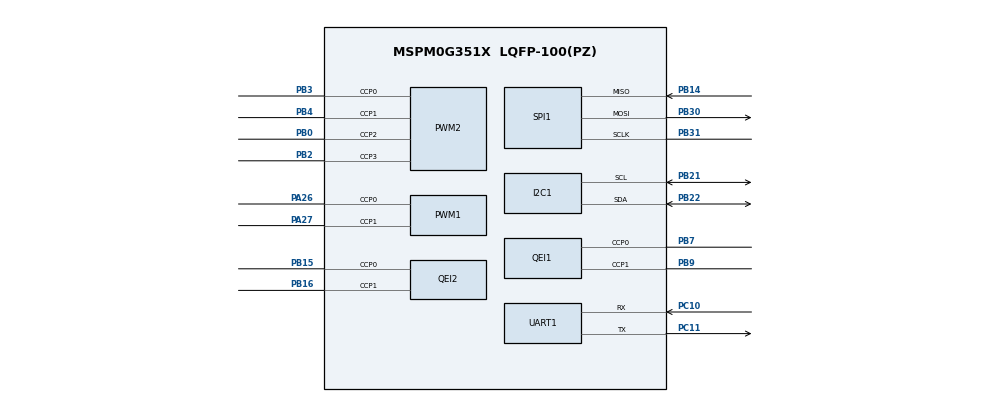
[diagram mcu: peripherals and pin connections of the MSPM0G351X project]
/**
 * @cliArgs --device "MSPM0G351X" --part "Default" --package "LQFP-100(PZ)" --product "mspm0_sdk@2.05.01.00"
 * @versions {"tool":"1.24.1+4189"}
 */

/**
 * Import the modules used in this configuration.
 */
const ADC12         = scripting.addModule("/ti/driverlib/ADC12", {}, false);
const ADC121        = ADC12.addInstance();
const Board         = scripting.addModule("/ti/driverlib/Board");
const GPIO          = scripting.addModule("/ti/driverlib/GPIO", {}, false);
const GPIO1         = GPIO.addInstance();
const GPIO2         = GPIO.addInstance();
const GPIO3         = GPIO.addInstance();
const I2C           = scripting.addModule("/ti/driverlib/I2C", {}, false);
const I2C1          = I2C.addInstance();
const PWM           = scripting.addModule("/ti/driverlib/PWM", {}, false);
const PWM1          = PWM.addInstance();
const PWM2          = PWM.addInstance();
const QEI           = scripting.addModule("/ti/driverlib/QEI", {}, false);
const QEI1          = QEI.addInstance();
const QEI2          = QEI.addInstance();
const SPI           = scripting.addModule("/ti/driverlib/SPI", {}, false);
const SPI1          = SPI.addInstance();
const SYSCTL        = scripting.addModule("/ti/driverlib/SYSCTL");
const SYSTICK       = scripting.addModule("/ti/driverlib/SYSTICK");
const UART          = scripting.addModule("/ti/driverlib/UART", {}, false);
const UART1         = UART.addInstance();
const ProjectConfig = scripting.addModule("/ti/project_config/ProjectConfig");

/**
 * Write custom configuration values to the imported modules.
 */
const divider9       = system.clockTree["UDIV"];
divider9.divideValue = 2;

const gate7  = system.clockTree["MFCLKGATE"];
gate7.enable = true;

const multiplier2         = system.clockTree["PLL_QDIV"];
multiplier2.multiplyValue = 4;

const mux4       = system.clockTree["EXHFMUX"];
mux4.inputSelect = "EXHFMUX_XTAL";

const mux5       = system.clockTree["EXLFMUX"];
mux5.inputSelect = "EXLFMUX_XTAL";

const mux8       = system.clockTree["HSCLKMUX"];
mux8.inputSelect = "HSCLKMUX_SYSPLL0";

const mux12       = system.clockTree["SYSPLLMUX"];
mux12.inputSelect = "zSYSPLLMUX_HFCLK";

const pinFunction4              = system.clockTree["HFXT"];
pinFunction4.enable             = true;
pinFunction4.inputFreq          = 40;
pinFunction4.HFXTStartup        = 16;
pinFunction4.peripheral.$assign = "SYSCTL";

const pinFunction6     = system.clockTree["LFXT"];
pinFunction6.inputFreq = 32.768;
pinFunction6.enable    = true;

ADC121.adcMem4chansel        = "DL_ADC12_INPUT_CHAN_4";
ADC121.$name                 = "CCD";
ADC121.adcMem4_name          = "CCD3_AO";
ADC121.adcMem2_name          = "CCD1_AO";
ADC121.adcMem2chansel        = "DL_ADC12_INPUT_CHAN_5";
ADC121.adcMem3_name          = "CCD2_AO";
ADC121.adcMem3chansel        = "DL_ADC12_INPUT_CHAN_6";
ADC121.adcMem6_name          = "CCD4_AO";
ADC121.adcMem6chansel        = "DL_ADC12_INPUT_CHAN_2";
ADC121.adcMem5chansel        = "DL_ADC12_INPUT_CHAN_6";
ADC121.adcMem5_name          = "CCD2_AO";
ADC121.adcMem0chansel        = "DL_ADC12_INPUT_CHAN_5";
ADC121.adcMem0_name          = "CCD1_AO";
ADC121.samplingOperationMode = "sequence";
ADC121.adcMem1_name          = "CCD2_AO";
ADC121.endAdd                = 1;
ADC121.adcMem1chansel        = "DL_ADC12_INPUT_CHAN_4";
ADC121.sampClkDiv            = "DL_ADC12_CLOCK_DIVIDE_8";
ADC121.powerDownMode         = "DL_ADC12_POWER_DOWN_MODE_MANUAL";
ADC121.sampleTime0           = "125 us";
ADC121.repeatMode            = true;
ADC121.enabledInterrupts     = ["DL_ADC12_INTERRUPT_MEM0_RESULT_LOADED","DL_ADC12_INTERRUPT_MEM1_RESULT_LOADED"];
ADC121.adcPin5Config.$name   = "ti_driverlib_gpio_GPIOPinGeneric17";
ADC121.peripheral.$assign    = "ADC1";
ADC121.adcPin4Config.$name   = "ti_driverlib_gpio_GPIOPinGeneric18";

Board.configureVDDA = true;

GPIO1.port                          = "PORTB";
GPIO1.$name                         = "PORTB";
GPIO1.associatedPins.create(5);
GPIO1.associatedPins[0].$name       = "LED";
GPIO1.associatedPins[0].ioStructure = "SD";
GPIO1.associatedPins[0].assignedPin = "5";
GPIO1.associatedPins[1].$name       = "CCD_CLK1";
GPIO1.associatedPins[1].assignedPin = "20";
GPIO1.associatedPins[2].$name       = "SLEEP";
GPIO1.associatedPins[2].assignedPin = "1";
GPIO1.associatedPins[3].$name       = "LCD_CS";
GPIO1.associatedPins[3].assignedPin = "28";
GPIO1.associatedPins[4].$name       = "LCD_DC";
GPIO1.associatedPins[4].assignedPin = "29";

GPIO2.port                          = "PORTA";
GPIO2.$name                         = "PORTA";
GPIO2.associatedPins.create(9);
GPIO2.associatedPins[0].direction   = "INPUT";
GPIO2.associatedPins[0].assignedPin = "18";
GPIO2.associatedPins[0].$name       = "S0";
GPIO2.associatedPins[1].direction   = "INPUT";
GPIO2.associatedPins[1].assignedPin = "14";
GPIO2.associatedPins[1].$name       = "PHA0";
GPIO2.associatedPins[1].interruptEn = true;
GPIO2.associatedPins[1].polarity    = "RISE_FALL";
GPIO2.associatedPins[2].$name       = "PHB0";
GPIO2.associatedPins[2].direction   = "INPUT";
GPIO2.associatedPins[2].assignedPin = "15";
GPIO2.associatedPins[3].$name       = "PUSH";
GPIO2.associatedPins[3].direction   = "INPUT";
GPIO2.associatedPins[3].assignedPin = "12";
GPIO2.associatedPins[4].$name       = "BUZZ";
GPIO2.associatedPins[4].assignedPin = "13";
GPIO2.associatedPins[5].$name       = "S2";
GPIO2.associatedPins[5].direction   = "INPUT";
GPIO2.associatedPins[5].assignedPin = "16";
GPIO2.associatedPins[6].$name       = "FAULT";
GPIO2.associatedPins[6].assignedPin = "7";
GPIO2.associatedPins[6].direction   = "INPUT";
GPIO2.associatedPins[7].$name       = "LCD_RST";
GPIO2.associatedPins[7].assignedPin = "8";
GPIO2.associatedPins[8].$name       = "LCD_BL";
GPIO2.associatedPins[8].assignedPin = "9";

GPIO3.port                          = "PORTC";
GPIO3.$name                         = "PORTC";
GPIO3.associatedPins.create(4);
GPIO3.associatedPins[0].$name       = "CCD_SI1";
GPIO3.associatedPins[0].assignedPin = "9";
GPIO3.associatedPins[1].$name       = "CCD_SI2";
GPIO3.associatedPins[1].assignedPin = "4";
GPIO3.associatedPins[2].$name       = "CCD_CLK2";
GPIO3.associatedPins[2].assignedPin = "5";
GPIO3.associatedPins[3].$name       = "S1";
GPIO3.associatedPins[3].direction   = "INPUT";
GPIO3.associatedPins[3].assignedPin = "0";

I2C1.$name                             = "MPU6050";
I2C1.basicEnableController             = true;
I2C1.basicControllerStandardBusSpeed   = "Fast";
I2C1.interruptPriority                 = "3";
I2C1.peripheral.$assign                = "I2C0";
I2C1.peripheral.sdaPin.$assign         = "PB22";
I2C1.peripheral.sclPin.$assign         = "PB21";
I2C1.sdaPinConfig.hideOutputInversion  = scripting.forceWrite(false);
I2C1.sdaPinConfig.onlyInternalResistor = scripting.forceWrite(false);
I2C1.sdaPinConfig.passedPeripheralType = scripting.forceWrite("Digital");
I2C1.sdaPinConfig.$name                = "ti_driverlib_gpio_GPIOPinGeneric11";
I2C1.sclPinConfig.hideOutputInversion  = scripting.forceWrite(false);
I2C1.sclPinConfig.onlyInternalResistor = scripting.forceWrite(false);
I2C1.sclPinConfig.passedPeripheralType = scripting.forceWrite("Digital");
I2C1.sclPinConfig.$name                = "ti_driverlib_gpio_GPIOPinGeneric12";

PWM1.$name                              = "Servo";
PWM1.clockPrescale                      = 100;
PWM1.timerCount                         = 4000;
PWM1.timerStartTimer                    = true;
PWM1.pwmMode                            = "EDGE_ALIGN_UP";
PWM1.peripheral.ccp0Pin.$assign         = "PA26";
PWM1.peripheral.ccp1Pin.$assign         = "PA27";
PWM1.PWM_CHANNEL_0.$name                = "ti_driverlib_pwm_PWMTimerCC0";
PWM1.PWM_CHANNEL_0.dutyCycle            = 50;
PWM1.PWM_CHANNEL_1.$name                = "ti_driverlib_pwm_PWMTimerCC1";
PWM1.PWM_CHANNEL_1.dutyCycle            = 50;
PWM1.ccp0PinConfig.direction            = scripting.forceWrite("OUTPUT");
PWM1.ccp0PinConfig.hideOutputInversion  = scripting.forceWrite(false);
PWM1.ccp0PinConfig.onlyInternalResistor = scripting.forceWrite(false);
PWM1.ccp0PinConfig.passedPeripheralType = scripting.forceWrite("Digital");
PWM1.ccp0PinConfig.$name                = "ti_driverlib_gpio_GPIOPinGeneric5";
PWM1.ccp1PinConfig.direction            = scripting.forceWrite("OUTPUT");
PWM1.ccp1PinConfig.hideOutputInversion  = scripting.forceWrite(false);
PWM1.ccp1PinConfig.onlyInternalResistor = scripting.forceWrite(false);
PWM1.ccp1PinConfig.passedPeripheralType = scripting.forceWrite("Digital");
PWM1.ccp1PinConfig.$name                = "ti_driverlib_gpio_GPIOPinGeneric6";

PWM2.$name                              = "Motor";
PWM2.clockDivider                       = 4;
PWM2.clockPrescale                      = 100;
PWM2.timerCount                         = 4000;
PWM2.ccIndex                            = [0,1,2,3];
PWM2.timerStartTimer                    = true;
PWM2.pwmMode                            = "EDGE_ALIGN_UP";
PWM2.PWM_CHANNEL_0.$name                = "ti_driverlib_pwm_PWMTimerCC2";
PWM2.PWM_CHANNEL_1.$name                = "ti_driverlib_pwm_PWMTimerCC3";
PWM2.ccp0PinConfig.direction            = scripting.forceWrite("OUTPUT");
PWM2.ccp0PinConfig.hideOutputInversion  = scripting.forceWrite(false);
PWM2.ccp0PinConfig.onlyInternalResistor = scripting.forceWrite(false);
PWM2.ccp0PinConfig.passedPeripheralType = scripting.forceWrite("Digital");
PWM2.ccp0PinConfig.$name                = "ti_driverlib_gpio_GPIOPinGeneric7";
PWM2.ccp1PinConfig.direction            = scripting.forceWrite("OUTPUT");
PWM2.ccp1PinConfig.hideOutputInversion  = scripting.forceWrite(false);
PWM2.ccp1PinConfig.onlyInternalResistor = scripting.forceWrite(false);
PWM2.ccp1PinConfig.passedPeripheralType = scripting.forceWrite("Digital");
PWM2.ccp1PinConfig.$name                = "ti_driverlib_gpio_GPIOPinGeneric8";
PWM2.peripheral.ccp0Pin.$assign         = "PB3";
PWM2.peripheral.ccp1Pin.$assign         = "PB4";
PWM2.peripheral.ccp2Pin.$assign         = "PB0";
PWM2.peripheral.ccp3Pin.$assign         = "PB2";
PWM2.PWM_CHANNEL_2.$name                = "ti_driverlib_pwm_PWMTimerCC4";
PWM2.PWM_CHANNEL_3.$name                = "ti_driverlib_pwm_PWMTimerCC5";
PWM2.ccp2PinConfig.$name                = "ti_driverlib_gpio_GPIOPinGeneric9";
PWM2.ccp3PinConfig.$name                = "ti_driverlib_gpio_GPIOPinGeneric10";

QEI1.timerStartTimer                    = true;
QEI1.$name                              = "QEI_1";
QEI1.peripheral.ccp0Pin.$assign         = "PB7";
QEI1.peripheral.ccp1Pin.$assign         = "PB9";
QEI1.ccp0PinConfig.hideOutputInversion  = scripting.forceWrite(false);
QEI1.ccp0PinConfig.onlyInternalResistor = scripting.forceWrite(false);
QEI1.ccp0PinConfig.passedPeripheralType = scripting.forceWrite("Digital");
QEI1.ccp0PinConfig.$name                = "ti_driverlib_gpio_GPIOPinGeneric13";
QEI1.ccp1PinConfig.hideOutputInversion  = scripting.forceWrite(false);
QEI1.ccp1PinConfig.onlyInternalResistor = scripting.forceWrite(false);
QEI1.ccp1PinConfig.passedPeripheralType = scripting.forceWrite("Digital");
QEI1.ccp1PinConfig.$name                = "ti_driverlib_gpio_GPIOPinGeneric14";

QEI2.$name                              = "QEI_2";
QEI2.timerStartTimer                    = true;
QEI2.peripheral.ccp0Pin.$assign         = "PB15";
QEI2.peripheral.ccp1Pin.$assign         = "PB16";
QEI2.ccp0PinConfig.hideOutputInversion  = scripting.forceWrite(false);
QEI2.ccp0PinConfig.onlyInternalResistor = scripting.forceWrite(false);
QEI2.ccp0PinConfig.passedPeripheralType = scripting.forceWrite("Digital");
QEI2.ccp0PinConfig.$name                = "ti_driverlib_gpio_GPIOPinGeneric15";
QEI2.ccp1PinConfig.hideOutputInversion  = scripting.forceWrite(false);
QEI2.ccp1PinConfig.onlyInternalResistor = scripting.forceWrite(false);
QEI2.ccp1PinConfig.passedPeripheralType = scripting.forceWrite("Digital");
QEI2.ccp1PinConfig.$name                = "ti_driverlib_gpio_GPIOPinGeneric16";

SPI1.$name                              = "LCD";
SPI1.enableDMAEvent1                    = false;
SPI1.enableDMAEvent2                    = false;
SPI1.targetBitRate                      = 10000000;
SPI1.frameFormat                        = "MOTO3";
SPI1.phase                              = "1";
SPI1.sclkPinConfig.direction            = scripting.forceWrite("OUTPUT");
SPI1.sclkPinConfig.onlyInternalResistor = scripting.forceWrite(false);
SPI1.sclkPinConfig.passedPeripheralType = scripting.forceWrite("Digital");
SPI1.sclkPinConfig.$name                = "ti_driverlib_gpio_GPIOPinGeneric0";
SPI1.sclkPinConfig.enableConfig         = true;
SPI1.mosiPinConfig.direction            = scripting.forceWrite("OUTPUT");
SPI1.mosiPinConfig.hideOutputInversion  = scripting.forceWrite(false);
SPI1.mosiPinConfig.onlyInternalResistor = scripting.forceWrite(false);
SPI1.mosiPinConfig.passedPeripheralType = scripting.forceWrite("Digital");
SPI1.mosiPinConfig.$name                = "ti_driverlib_gpio_GPIOPinGeneric1";
SPI1.mosiPinConfig.enableConfig         = true;
SPI1.misoPinConfig.onlyInternalResistor = scripting.forceWrite(false);
SPI1.misoPinConfig.passedPeripheralType = scripting.forceWrite("Digital");
SPI1.misoPinConfig.$name                = "ti_driverlib_gpio_GPIOPinGeneric2";
SPI1.peripheral.$assign                 = "SPI1";
SPI1.peripheral.sclkPin.$assign         = "PB31";
SPI1.peripheral.mosiPin.$assign         = "PB30";
SPI1.peripheral.misoPin.$assign         = "PB14";

SYSCTL.clockTreeEn = true;
scripting.suppress("For best practices when the CPUCLK is running at 32MHz and above, clear the flash status bit using DL_FlashCTL_executeClearStatus\\(\\) before executing any flash operation\\. Otherwise there may be false positives\\.", SYSCTL);

SYSTICK.periodEnable    = true;
SYSTICK.interruptEnable = true;
SYSTICK.systickEnable   = true;
SYSTICK.period          = 80000;

UART1.$name                            = "K230";
UART1.targetBaudRate                   = 115200;
UART1.enabledInterrupts                = ["RXD_POS_EDGE"];
UART1.peripheral.$assign               = "UART6";
UART1.peripheral.rxPin.$assign         = "PC10";
UART1.peripheral.txPin.$assign         = "PC11";
UART1.txPinConfig.direction            = scripting.forceWrite("OUTPUT");
UART1.txPinConfig.hideOutputInversion  = scripting.forceWrite(false);
UART1.txPinConfig.onlyInternalResistor = scripting.forceWrite(false);
UART1.txPinConfig.passedPeripheralType = scripting.forceWrite("Digital");
UART1.txPinConfig.$name                = "ti_driverlib_gpio_GPIOPinGeneric3";
UART1.rxPinConfig.hideOutputInversion  = scripting.forceWrite(false);
UART1.rxPinConfig.onlyInternalResistor = scripting.forceWrite(false);
UART1.rxPinConfig.passedPeripheralType = scripting.forceWrite("Digital");
UART1.rxPinConfig.$name                = "ti_driverlib_gpio_GPIOPinGeneric4";

ProjectConfig.deviceSpin = "MSPM0G3519";

/**
 * Pinmux solution for unlocked pins/peripherals. This ensures that minor changes to the automatic solver in a future
 * version of the tool will not impact the pinmux you originally saw.  These lines can be completely deleted in order to
 * re-solve from scratch.
 */
pinFunction4.peripheral.hfxInPin.$suggestSolution  = "PA5";
pinFunction4.peripheral.hfxOutPin.$suggestSolution = "PA6";
pinFunction6.peripheral.$suggestSolution           = "SYSCTL";
pinFunction6.peripheral.lfxInPin.$suggestSolution  = "PA3";
pinFunction6.peripheral.lfxOutPin.$suggestSolution = "PA4";
ADC121.peripheral.adcPin5.$suggestSolution         = "PB18";
ADC121.peripheral.adcPin4.$suggestSolution         = "PB17";
Board.peripheral.$suggestSolution                  = "DEBUGSS";
Board.peripheral.swclkPin.$suggestSolution         = "PA20";
Board.peripheral.swdioPin.$suggestSolution         = "PA19";
GPIO1.associatedPins[0].pin.$suggestSolution       = "PB5";
GPIO1.associatedPins[1].pin.$suggestSolution       = "PB20";
GPIO1.associatedPins[2].pin.$suggestSolution       = "PB1";
GPIO1.associatedPins[3].pin.$suggestSolution       = "PB28";
GPIO1.associatedPins[4].pin.$suggestSolution       = "PB29";
GPIO2.associatedPins[0].pin.$suggestSolution       = "PA18";
GPIO2.associatedPins[1].pin.$suggestSolution       = "PA14";
GPIO2.associatedPins[2].pin.$suggestSolution       = "PA15";
GPIO2.associatedPins[3].pin.$suggestSolution       = "PA12";
GPIO2.associatedPins[4].pin.$suggestSolution       = "PA13";
GPIO2.associatedPins[5].pin.$suggestSolution       = "PA16";
GPIO2.associatedPins[6].pin.$suggestSolution       = "PA7";
GPIO2.associatedPins[7].pin.$suggestSolution       = "PA8";
GPIO2.associatedPins[8].pin.$suggestSolution       = "PA9";
GPIO3.associatedPins[0].pin.$suggestSolution       = "PC9";
GPIO3.associatedPins[1].pin.$suggestSolution       = "PC4";
GPIO3.associatedPins[2].pin.$suggestSolution       = "PC5";
GPIO3.associatedPins[3].pin.$suggestSolution       = "PC0";
PWM1.peripheral.$suggestSolution                   = "TIMG7";
PWM2.peripheral.$suggestSolution                   = "TIMA0";
QEI1.peripheral.$suggestSolution                   = "TIMG9";
QEI2.peripheral.$suggestSolution                   = "TIMG8";
